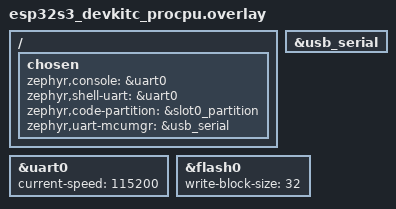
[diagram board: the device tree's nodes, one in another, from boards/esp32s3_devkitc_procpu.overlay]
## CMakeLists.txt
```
# SPDX-License-Identifier: Apache-2.0

cmake_minimum_required(VERSION 3.28.0)

find_package(Zephyr REQUIRED HINTS $ENV{ZEPHYR_BASE})
project(hello_world)

zephyr_code_relocate(FILES ${ZEPHYR_BASE}/samples/hello_world/src/main.c LATECOPY LOCATION PSRAM)

target_sources(app PRIVATE src/main.c)
```

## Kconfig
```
config IMAGE_NAME
	string "Image name"
	default "Default"

source "Kconfig.zephyr"
```

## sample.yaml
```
sample:
  description: Hello World sample, the simplest Zephyr
    application
  name: hello world
common:
  min_ram: 2
  min_flash: 16
  tags: introduction
  integration_platforms:
    - native_sim
    - mini_stm32h7b0
  harness: console
  harness_config:
    type: one_line
    regex:
      - "Hello World! (.*)"
tests:
  sample.basic.helloworld:
    tags: introduction
```

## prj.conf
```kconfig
# nothing here
CONFIG_PM_DEVICE=y

CONFIG_SHELL=y
CONFIG_DEVICE_SHELL=y
CONFIG_PM_DEVICE_SHELL=y

CONFIG_LOG=y
CONFIG_POWER_DOMAIN_LOG_LEVEL_DBG=y
```

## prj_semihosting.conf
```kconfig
# nothing here
CONFIG_SCHED_MULTIQ=y
CONFIG_SEMIHOSTING_CONSOLE=y
CONFIG_SERIAL=n
```

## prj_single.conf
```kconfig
CONFIG_MULTITHREADING=n
CONFIG_SIMPLE_PROCESS_SLOWDOWN_TO_REAL_TIME=y
```

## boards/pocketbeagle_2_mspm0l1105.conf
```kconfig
# Enable Console
CONFIG_SERIAL=y
CONFIG_CONSOLE=y
CONFIG_UART_CONSOLE=y
```

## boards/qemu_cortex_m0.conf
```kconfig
# Make this as small an example as possible
CONFIG_MULTITHREADING=n
CONFIG_NRF_TIMER_TIMER=n
```

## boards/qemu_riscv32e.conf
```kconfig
# Make this as small an example as possible
CONFIG_MULTITHREADING=n
CONFIG_RISCV_PMP=n
```

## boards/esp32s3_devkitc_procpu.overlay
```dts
/ {
	chosen {
		zephyr,console = &uart0;
		zephyr,shell-uart = &uart0;
		zephyr,code-partition = &slot0_partition;
		zephyr,uart-mcumgr = &usb_serial;
	};
};

&uart0 {
	current-speed = <115200>;
};

&usb_serial {
	status = "okay";
};

&flash0 {
       write-block-size = <32>;
};
```

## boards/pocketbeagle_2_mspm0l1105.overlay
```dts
/*
 * Copyright (c) 2025 Ayush Singh, BeagleBoard.org Foundation
 *
 * SPDX-License-Identifier: Apache-2.0
 *
 * Sample overlay for using UART on PocketBeagle 2 MSPM0.
 *
 * P1_25 = UART TX
 * P1_27 = UART RX
 */

/ {
	chosen {
		zephyr,console = &uart0;
	};
};

&uart0 {
	status = "okay";
	pinctrl-names = "default";
	pinctrl-0 = <&uart0_rx_pa26 &uart0_tx_pa25>;
};
```

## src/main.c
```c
/*
 * Copyright (c) 2012-2014 Wind River Systems, Inc.
 *
 * SPDX-License-Identifier: Apache-2.0
 */

#include <stdio.h>

int main(void)
{
	printf("Hello World! %s\n", CONFIG_BOARD_TARGET);
	printf("Hello World! %s\n", "RTK_JACK");

	return 0;
}
```

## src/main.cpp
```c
/*
 * Copyright (c) 2012-2014 Wind River Systems, Inc.
 *
 * SPDX-License-Identifier: Apache-2.0
 */

#include <zephyr.h>
#include <sys/printk.h>

void main(void)
{
	printk("Hello World! %s\n", CONFIG_BOARD);

	try
	{
		printk("Throwing integer exception 20.\n");
		throw 20;
	}
	catch (int e)
	{
		printk("An integer exception occurred and was handled.\n");
	}
	catch (bool e)
	{
		printk("A bool exception occurred and was handled.\n");
	}
	catch (void* e)
	{
		printk("A C++ void exception occurred and was handled.\n");
	}
}
```
